# STM32H733 register map
File version: 1.8
CPU: CM7 r0p1, little endian, MPU, FPU, 4 interrupt priority bits
Registers are 32-bit, read-write, reset 0x0 unless marked. A register's access mark holds for its fields unless they carry their own. Offsets are from the block's base; [hi:lo] are bit positions.

## CORDIC — CORDIC register block
Base 0x48024400
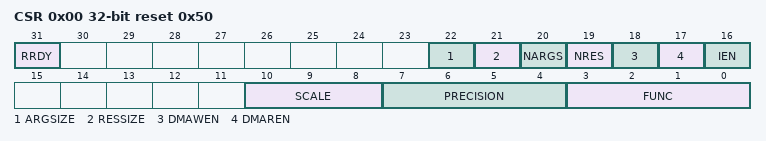
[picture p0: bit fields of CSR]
0x00 CSR access per field reset 0x50 — CORDIC control/status register
  [31] RRDY ro — Result ready flag This bit is set by hardware when a CORDIC operation completes. It is reset by hardware when the CORDIC_RDATA register is read (NRES+1) times. When this bit is set, if the IEN bit is also set, the CORDIC interrupt is asserted. If the DMAREN bit is set, a DMA read channel request is generated. While this bit is set, no new calculation is started.
    0=NotReady (Results from computation are not read); 1=Ready (Results are ready, this flag will be automatically cleared once value is read)
  [22] ARGSIZE rw — Width of input data ARGSIZE selects the number of bits used to represent input data. If 32-bit data is selected, the CORDIC_WDATA register expects arguments in q1.31 format. If 16-bit data is selected, the CORDIC_WDATA register expects arguments in q1.15 format. The primary argument (ARG1) is written to the least significant half-word, and the secondary argument (ARG2) to the most significant half-word.
    0=Bits32 (Use 32 bit input values); 1=Bits16 (Use 16 bit input values)
  [21] RESSIZE rw — Width of output data RESSIZE selects the number of bits used to represent output data. If 32-bit data is selected, the CORDIC_RDATA register contains results in q1.31 format. If 16-bit data is selected, the least significant half-word of CORDIC_RDATA contains the primary result (RES1) in q1.15 format, and the most significant half-word contains the secondary result (RES2), also in q1.15 format.
    0=Bits32 (Use 32 bit output values); 1=Bits16 (Use 16 bit output values)
  [20] NARGS rw — Number of arguments expected by the CORDIC_WDATA register Reads return the current state of the bit.
    0=Num1 (Only single argument write is needed for next calculation); 1=Num2 (Two argument writes need to be performed for next calculation)
  [19] NRES rw — Number of results in the CORDIC_RDATA register Reads return the current state of the bit.
    0=Num1 (Only single result value will be returned. After a single read RRDY will be automatically cleared); 1=Num2 (Two return reads need to be performed. After two reads RRDY will be automatically cleared)
  [18] DMAWEN rw — Enable DMA write channel This bit is set and cleared by software. A read returns the current state of the bit.
    0=Disabled (No DMA channel writes are generated); 1=Enabled (Write requests are generated on the DMA channel when no operation is pending)
  [17] DMAREN rw — Enable DMA read channel This bit is set and cleared by software. A read returns the current state of the bit.
    0=Disabled (No DMA channel reads are generated); 1=Enabled (Read requests are generated on the DMA channel when RRDY flag is set)
  [16] IEN rw — Enable interrupt. This bit is set and cleared by software. A read returns the current state of the bit.
    0=Disabled (Disable interrupt request generation); 1=Enabled (Enable interrupt request generation)
  [10:8] SCALE rw — Scaling factor The value of this field indicates the scaling factor applied to the arguments and/or results. A value n implies that the arguments have been multiplied by a factor 2-n, and/or the results need to be multiplied by 2n. Refer to for the applicability of the scaling factor for each function and the appropriate range.
  [7:4] PRECISION rw — Precision required (number of iterations) To determine the number of iterations needed for a given accuracy refer to . Note that for most functions, the recommended range for this field is 3 to 6.
    1=Iters4 (4 iterations); 2=Iters8 (8 iterations); 3=Iters12 (12 iterations); 4=Iters16 (16 iterations); 5=Iters20 (20 iterations); 6=Iters24 (24 iterations); 7=Iters28 (28 iterations); 8=Iters32 (32 iterations); 9=Iters36 (36 iterations); 10=Iters40 (40 iterations); 11=Iters44 (44 iterations); 12=Iters48 (48 iterations); 13=Iters52 (52 iterations); 14=Iters56 (56 iterations); 15=Iters60 (60 iterations)
  [3:0] FUNC rw — Function
    0=Cosine function; 1=Sine function; 2=Phase function; 3=Modulus function; 4=Arctangent function; 5=Hyperbolic Cosine function; 6=Hyperbolic Sine function; 7=Arctanh function; 8=Natural Logarithm function; 9=Square Root function
0x04 WDATA wo reset not defined — CORDIC argument register
  [31:0] ARG — Function input arguments This register is programmed with the input arguments for the function selected in the CORDIC_CSR register FUNC field. If 32-bit format is selected (CORDIC_CSR.ARGSIZE = 0) and two input arguments are required (CORDIC_CSR.NARGS = 1), two successive writes are required to this register. The first writes the primary argument (ARG1), the second writes the secondary argument (ARG2). If 32-bit format is selected and only one input argument is required (NARGS = 0), only one write is required to this register, containing the primary argument (ARG1). If 16-bit format is selected (CORDIC_CSR.ARGSIZE = 1), one write to this register contains both arguments. The primary argument (ARG1) is in the lower half, ARG[15:0], and the secondary argument (ARG2) is in the upper half, ARG[31:16]. In this case, NARGS must be set to 0. Refer to for the arguments required by each function, and their permitted range. When the required number of arguments has been written, the CORDIC evaluates the function designated by CORDIC_CSR.FUNC using the supplied input arguments, provided any previous calculation has completed. If a calculation is ongoing, the ARG1 and ARG 2 values are held pending until the calculation is completed and the results read. During this time, a write to the register cancels the pending operation and overwrite the argument data.
0x08 RDATA ro — CORDIC result register
  [31:0] RES — Function result If 32-bit format is selected (CORDIC_CSR.RESSIZE = 0) and two output values are expected (CORDIC_CSR.NRES = 1), this register must be read twice when the RRDY flag is set. The first read fetches the primary result (RES1). The second read fetches the secondary result (RES2) and resets RRDY. If 32-bit format is selected and only one output value is expected (NRES = 0), only one read of this register is required to fetch the primary result (RES1) and reset the RRDY flag. If 16-bit format is selected (CORDIC_CSR.RESSIZE = 1), this register contains the primary result (RES1) in the lower half, RES[15:0], and the secondary result (RES2) in the upper half, RES[31:16]. In this case, NRES must be set to 0, and only one read performed. A read from this register resets the RRDY flag in the CORDIC_CSR register.
